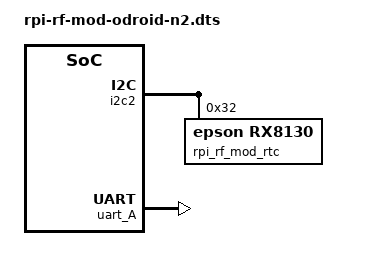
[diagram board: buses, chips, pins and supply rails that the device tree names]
/dts-v1/;
/plugin/;

/*
** Device Tree Overlay for eQ-3 RPI-RF-MOD and
** HM-MOD-RPI-PCB for ODROID-N2/N2+
**
** Copyright (c) 2021 Jens Maus <mail@jens-maus.de>
** Licensed under Apache 2.0
**
*/

/ {
    compatible = "hardkernel,odroid-n2-plus", "hardkernel,odroid-n2", "amlogic,s922x", "amlogic,g12b";

    // fragment to define settings for the rx8130 RTC clock
    // of the RPI-RF-MOD
    fragment@0 {
        target = <&i2c2>;
        __overlay__ {
            #address-cells = <1>;
            #size-cells = <0>;
            status = "okay";

            rpi_rf_mod_rtc: rx8130@32 {
                compatible = "epson,rx8130";
                reg = <0x32>;
                status = "okay";
                aux-voltage-chargeable = <1>;
            };
        };
    };

    // fragment to define uart/serial dependencies for
    // generic_raw_uart
    fragment@1 {
        target = <&uart_A>;
        __overlay__ {
            compatible = "pivccu,meson";
            status = "okay";
            pivccu,reset_pin = <&gpio 81 0>;    // HM-MOD-RPI-PCB
            pivccu,alt_reset_pin = <&gpio 84 0>;// RPI-RF-MOD
            pivccu,rtc = <&rpi_rf_mod_rtc>;     // RPI-RF-MOD
        };
    };

    // swap i2c2 and i2c3 so that we have the i2c1 alias mapped to i2c3 instead
    fragment@2 {
        target-path = "/";
        __overlay__ {
            aliases {
                i2c0 = <&i2c3>;
                i2c1 = <&i2c2>;
            };
        };
    };
};
